# NUC100DN_v1 register map
File version: 1.0
Registers are 32-bit, read-write, reset 0x0 unless marked. A register's access mark holds for its fields unless they carry their own. Offsets are from the block's base; [hi:lo] are bit positions.

## SC0 — SC Register Map
Base 0x40190000
Same registers: SC1 0x40194000, SC2 0x40198000
0x00 SC_RBR ro reset not defined — SC Receiving Buffer Register.
  [7:0] RBR — Receive Buffer Register. By reading this register, the SC will return an 8-bit received data.
0x00 SC_THR wo reset not defined (alternate view of SC_RBR) — SC Transmit Holding Register
  [7:0] THR — Transmit Holding Register. By writing to this register, the SC will send out an 8-bit data. Note: If SC_CTL[SC_CEN] not enabled, this register cannot be programmed.
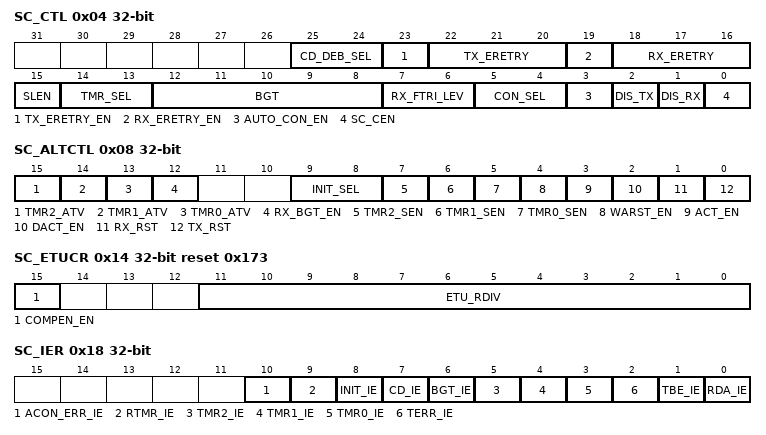
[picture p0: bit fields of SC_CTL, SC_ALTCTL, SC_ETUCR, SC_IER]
0x04 SC_CTL — SC Control Register
  [25:24] CD_DEB_SEL — Card Detect De-bounce Selection. This field indicates the card detect de-bounce selection.
    0=De-bounce sample card insert once per 384 (128 * 3) peripheral clocks and de-bounce sample card removal once per 128 peripheral clocks; 1=De-bounce sample card insert once per 192 (64 * 3) peripheral clocks and de-bounce sample card removal once per 64 peripheral clocks; 2=De-bounce sample card insert once per 96 (32 * 3) peripheral clocks and de-bounce sample card removal once per 32 peripheral clocks; 3=De-bounce sample card insert once per 48 (16 * 3) peripheral clocks and de-bounce sample card removal once per 16 peripheral clocks
  [23] TX_ERETRY_EN — TX Error Retry Enable Bit. This bit enables transmitter retry function when parity error has occurred. Note: Software must fill in TX_ERETRY value before enabling this bit.
    0=TX error retry function Disabled; 1=TX error retry function Enabled
  [22:20] TX_ERETRY — TX Error Retry Count. This field indicates the maximum number of transmitter retries that are allowed when parity error has occurred. Note1: The real retry number is TX_ERETRY + 1, and 8 is the maximum retry number. Note2: This field cannot be changed when TX_ERETRY_EN is enabled. The change flow is to disable TX_ETRTRY_EN first and then fill in a new retry value.
  [19] RX_ERETRY_EN — RX Error Retry Enable Bit. This bit enables receiver retry function when parity error has occurred. Note: Software must fill in RX_ERETRY value before enabling this bit.
    0=RX error retry function Disabled; 1=RX error retry function Enabled
  [18:16] RX_ERETRY — RX Error Retry Count. This field indicates the maximum number of receiver retries that are allowed when parity error has occurred. Note1: The real maximum retry number is RX_ERETRY + 1, so 8 is the maximum retry number. Note2: This field cannot be changed when RX_ERETRY_EN enabled. The change flow is to disable RX_ETRTRY_EN first and then fill new retry value.
  [15] SLEN — Stop Bit Length. This field indicates the length of stop bit. Note: The default stop bit length is 2.
    0=The stop bit length is 2 ETU; 1=The stop bit length is 1 ETU
  [14:13] TMR_SEL — Timer Selection
    0=All internal timer functions Disabled; 1=Internal 24-bit timer Enabled. Software can configure it by setting SC_TMR0 [23:0]. SC_TMR1 and SC_TMR2 will be ignored in this mode; 2=Internal 24-bit timer and 8-bit internal timer Enabled. Software can configure the 24-bit timer by setting SC_TMR0 [23:0] and configure the 8-bit timer by setting SC_TMR1[7:0]. SC_TMR2 will be ignored in this mode; 3=Internal 24-bit timer and two 8-bit timers Enabled. Software can configure them by setting SC_TMR0 [23:0], SC_TMR1 [7:0] and SC_TMR2 [7:0]
  [12:8] BGT — Block Guard Time (BGT). Note: The real block guard time is BGT + 1.
  [7:6] RX_FTRI_LEV — Rx Buffer Trigger Level. When the number of bytes in the receiving buffer equals the RX_FTRI_LEV, the RDA_IF will be set (if IER [RDA_IEN] is enabled, an interrupt will be generated).
    0=INTR_RDA Trigger Level with 1 Byte; 1=INTR_RDA Trigger Level with 2 Bytes; 2=INTR_RDA Trigger Level with 3 Bytes
  [5:4] CON_SEL — Convention Selection. Note: If AUTO_CON_EN enabled, this fields must be ignored.
    0=Direct convention; 3=Inverse convention
  [3] AUTO_CON_EN — Auto Convention Enable Bit
    0=Auto-convention Disabled; 1=Auto-convention Enabled
  [2] DIS_TX — TX Transition Disable Bit
    0=Transceiver Enabled; 1=Transceiver Disabled
  [1] DIS_RX — RX Transition Disable Bit. Note: If AUTO_CON_EN enabled, this fields must be ignored.
    0=Receiver Enabled; 1=Receiver Disabled
  [0] SC_CEN — SC Engine Enable Bit. Setting this bit to "1" will enable SC operation. If this bit is cleared, SC will force all transition to IDLE state.
0x08 SC_ALTCTL — SC Alternate Control State Register
  [15] TMR2_ATV ro — Internal Timer2 Active State (Read Only). This bit indicates the Timer2 counter status
    0=Timer2 is not active; 1=Timer2 is active
  [14] TMR1_ATV ro — Internal Timer1 Active State (Read Only). This bit indicates the Timer1 counter status
    0=Timer1 is not active; 1=Timer1 is active
  [13] TMR0_ATV ro — Internal Timer0 Active State (Read Only). This bit indicates the Timer0 counter status
    0=Timer0 is not active; 1=Timer0 is active
  [12] RX_BGT_EN — Check Receiver Block Guard Time Function Enable
    0=Check receiver block guard time function Disabled; 1=Check receiver block guard time function Enabled
  [9:8] INIT_SEL — Initial Timing Selection. This fields indicates the timing of hardware initial state (activation or warm-reset or deactivation). Unit: SC clock. Activation: refer to Figure 679. Warm-reset: refer to Figure 680. Deactivation: refer to Figure 681.
  [7] TMR2_SEN — Internal Timer2 Start Enable Bit. This bit enables Timer2 to start counting. Software can fill "0" to stop it and set "1" to reload and count. Note3: This field will be cleared when software set SC_ALTCTL[TX_RST] or SC_ALTCTL [RX_RST] to 1. So don't fill this bit, TX_RST, and RX_RST at the same time. Note4: If SC_CTL [SC_CEN] not enabled, this field cannot be programmed.
    0=Stops counting; 1=Starts counting
  [6] TMR1_SEN — Internal Timer1 Start Enable Bit. This bit enables Timer1 to start counting. Software can fill "0" to stop it and set "1" to reload and count. Note3: This field will be cleared when software set SC_ALTCTL[TX_RST] or SC_ALTCTL[RX_RST] to 1, so don't fill this bit, TX_RST, and RX_RST at the same time. Note4: If SC_CTL [SC_CEN] not enabled, this field cannot be programmed.
    0=Stops counting; 1=Starts counting
  [5] TMR0_SEN — Internal Timer0 Start Enable Bit. This bit enables Timer0 to start counting. Software can fill "0" to stop it and set "1" to reload and count. Note3: This field will be cleared when software set SC_ALTCTL[TX_RST] or SC_ALTCTL[RX_RST] to 1. So don't fill this bit, TX_RST and RX_RST at the same time. Note4: If SC_CTL [SC_CEN] not enabled, this field cannot be programmed.
    0=Stops counting; 1=Starts counting
  [4] WARST_EN — Warm Reset Sequence Generator Enable Bit. This bit enables SC controller to initiate the card by warm reset sequence. Note1: When the warm reset sequence completed, this bit will be cleared automatically and the SC_ISR[INIT_IS] will be set to "1". Note2: This field will be cleared when software set SC_ALTCTL[TX_RST] or SC_ALTCTL[RX_RST] to 1. So don't fill this bit, TX_RST, and RX_RST at the same time. Note3: If SC_CTL[SC_CEN] not enabled, this field cannot be programmed.
    0=No effect; 1=Warm reset sequence generator Enabled
  [3] ACT_EN — Activation Sequence Generator Enable Bit. This bit enables SC controller to initiate the card by activation sequence. Note1: When the activation sequence completed, this bit will be cleared automatically and the SC_ISR [INIT_IS] will be set to "1". Note2: This field will be cleared when software set SC_ALTCTL[TX_RST] or SC_ALTCTL[RX_RST] to 1. So don't fill this bit, TX_RST, and RX_RST at the same time. Note3: If SC_CTL[SC_CEN] not enabled, this field cannot be programmed.
    0=No effect; 1=Activation sequence generator Enabled
  [2] DACT_EN — Deactivation Sequence Generator Enable Bit. This bit enables SC controller to initiate the card by deactivation sequence. Note1: When the deactivation sequence completed, this bit will be cleared automatically and the SC_ISR [INIT_IS] will be set to "1". Note2: This field will be cleared when software set SC_ALTCTL[TX_RST] or SC_ALTCTL[RX_RST] to 1. So don't fill this bit, TX_RST, and RX_RST at the same time. Note3: If SC_CTL [SC_CEN] not enabled, this field cannot be programmed.
    0=No effect; 1=Deactivation sequence generator Enabled
  [1] RX_RST — Rx Software Reset. When RX_RST is set, all the bytes in the receiver buffer and Rx internal state machine will be cleared. Note: This bit will be auto cleared and it needs at least 3 SC peripheral clock cycles.
    0=No effect; 1=Reset the Rx internal state machine and pointers
  [0] TX_RST — TX Software Reset. When TX_RST is set, all the bytes in the transmit buffer and TX internal state machine will be cleared. Note: This bit will be auto cleared and it needs at least 3 SC peripheral clock cycles.
    0=No effect; 1=Reset the TX internal state machine and pointers
0x0C SC_EGTR — SC Extend Guard Time Register
  [7:0] EGT — Extended Guard Time. This field indicates the extended guard time value. Note: The counter is ETU based and the real extended guard time is EGT.
0x10 SC_RFTMR — SC Receiver Buffer Time-out Register
  [8:0] RFTM — SC Receiver Buffer Time-out Register (ETU Based). Note1: The counter unit is ETU based and the interval of time-out is RFTM + 0.5. Note2: Filling all "0" to this field indicates to disable this function.
0x14 SC_ETUCR reset 0x173 — SC ETU Control Register
  [15] COMPEN_EN — Compensation Mode Enable Bit. This bit enables clock compensation function. When this bit enabled, hardware will alternate between n-1 clock cycles and n clock cycles, where n is the value to be written into the ETU_RDIV register.
    0=Compensation function Disabled; 1=Compensation function Enabled
  [11:0] ETU_RDIV — ETU Rate Divider. The field indicates the clock rate divider. The real ETU is ETU_RDIV + 1. Note1: Software can configure this field, but this field must be greater than 0x04. Note2: Software can configure this field, but if the error rate is equal to 2%, this field must be greater than 0x040.
0x18 SC_IER — SC Interrupt Enable Register
  [10] ACON_ERR_IE — Auto Convention Error Interrupt Enable Bit. This field is used for auto-convention error interrupt enable.
    0=Auto-convention error interrupt Disabled; 1=Auto-convention error interrupt Enabled
  [9] RTMR_IE — Receiver Buffer Time-out Interrupt Enable Bit. This field is used for receiver buffer time-out interrupt enable.
    0=Receiver buffer time-out interrupt Disabled; 1=Receiver buffer time-out interrupt Enabled
  [8] INIT_IE — Initial End Interrupt Enable Bit. This field is used for activation (SC_ALTCTL [ACT_EN]), deactivation (SC_ALTCTL [DACT_EN]) and warm reset (SC_ALTCTL [WARST_EN]) sequence interrupt enable.
    0=Initial end interrupt Disabled; 1=Initial end interrupt Enabled
  [7] CD_IE — Card Detect Interrupt Enable Bit. This field is used for card detect interrupt enable. The card detect status register is SC_PINCSR[CD_INS_F] and SC_PINCSR[CD_REM_F].
    0=Card detect interrupt Disabled; 1=Card detect interrupt Enabled
  [6] BGT_IE — Block Guard Time Interrupt Enable Bit. This field is used for block guard time interrupt enable.
    0=Block guard time Disabled; 1=Block guard time Enabled
  [5] TMR2_IE — Timer2 Interrupt Enable Bit. This field is used for TMR2 interrupt enable.
    0=Timer2 interrupt Disabled; 1=Timer2 interrupt Enabled
  [4] TMR1_IE — Timer1 Interrupt Enable Bit. This field is used for TMR1 interrupt enable.
    0=Timer1 interrupt Disabled; 1=Timer1 interrupt Enabled
  [3] TMR0_IE — Timer0 Interrupt Enable Bit. This field is used for TMR0 interrupt enable.
    0=Timer0 interrupt Disabled; 1=Timer0 interrupt Enabled
  [2] TERR_IE — Transfer Error Interrupt Enable Bit. This field is used for transfer error interrupt enable. The transfer error states is at SC_TRSR register which includes receiver break error (RX_EBR_F), frame error (RX_EFR_F), parity error (RX_EPA_F), receiver buffer overflow error (RX_OVER_F), transmit buffer overflow error (TX_OVER_F), receiver retry over limit error (RX_OVER_REERR) and transmitter retry over limit error (TX_OVER_REERR).
    0=Transfer error interrupt Disabled; 1=Transfer error interrupt Enabled
  [1] TBE_IE — Transmit Buffer Empty Interrupt Enable Bit. This field is used for transmit buffer empty interrupt enable.
    0=Transmit buffer empty interrupt Disabled; 1=Transmit buffer empty interrupt Enabled
  [0] RDA_IE — Receive Data Reach Interrupt Enable Bit. This field is used for received data reaching trigger level (SC_CTL [RX_FTRI_LEV]) interrupt enable.
    0=Receive data reach trigger level interrupt Disabled; 1=Receive data reach trigger level interrupt Enabled
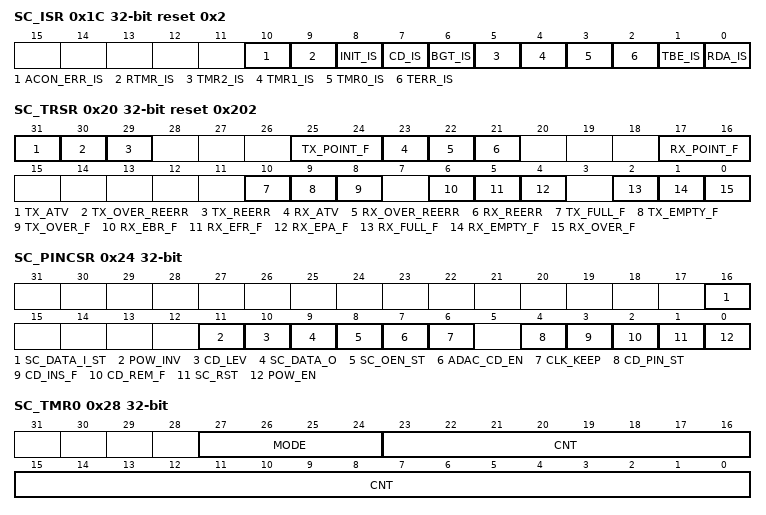
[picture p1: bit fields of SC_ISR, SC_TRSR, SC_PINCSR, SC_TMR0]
0x1C SC_ISR reset 0x2 — SC Interrupt Status Register
  [10] ACON_ERR_IS ro — Auto Convention Error Interrupt Status Flag (Read Only). This field indicates auto convention sequence error. If the received TS at ATR state is not 0x3B or 0x3F, this bit will be set. Note: This bit is read only, but can be cleared by writing "1" to it.
  [9] RTMR_IS ro — Receiver Buffer Time-out Interrupt Status Flag (Read Only). This field is used for receiver buffer time-out interrupt status flag. Note: This field is the status flag of receiver buffer time-out state. If software wants to clear this bit, software must read the receiver buffer remaining data by reading SC_RBR register,
  [8] INIT_IS ro — Initial End Interrupt Status Flag (Read Only). This field is used for activation (SC_ALTCTL [ACT_EN]), deactivation (SC_ALTCTL [DACT_EN]) and warm reset (SC_ALTCTL [WARST_EN]) sequence interrupt status flag. Note: This bit is read only, but it can be cleared by writing "1" to it.
  [7] CD_IS ro — Card Detect Interrupt Status Flag (Read Only). Note: If software wants to clear this field, software must clear SC_PINCSR [CD_INS_F] and SC_PINCSR [CD_REM_F].
  [6] BGT_IS ro — Block Guard Time Interrupt Status Flag (Read Only). This field is used for block guard time interrupt status flag. Note1: This bit is valid when SC_ALTCTL[RX_BGT_EN] is enabled. Note2: This bit is read only, but it can be cleared by writing "1" to it.
  [5] TMR2_IS ro — Timer2 Interrupt Status Flag (Read Only). This field is used for TMR2 interrupt status flag. Note: This bit is read only, but it can be cleared by writing "1" to it.
  [4] TMR1_IS ro — Timer1 Interrupt Status Flag (Read Only). This field is used for TMR1 interrupt status flag. Note: This bit is read only, but it can be cleared by writing "1" to it.
  [3] TMR0_IS ro — Timer0 Interrupt Status Flag (Read Only). This field is used for TMR0 interrupt status flag. Note: This bit is read only, but it can be cleared by writing "1" to it.
  [2] TERR_IS ro — Transfer Error Interrupt Status Flag (Read Only). This field is used for transfer error interrupt status flag. The transfer error status is at the SC_TRSR register which includes receiver break error (RX_EBR_F), frame error (RX_EFR_F), parity error (RX_EPA_F) and receiver buffer overflow error (RX_OVER_F), transmit buffer overflow error (TX_OVER_F), receiver retry over limit error (RX_OVER_REERR) and transmitter retry over limit error (TX_OVER_REERR). Note: This field is the status flag of SC_TRSR[RX_EBR_F], SC_TRSR[RX_EFR_F], SC_TRSR[RX_EPA_F], SC_TRSR[RX_OVER_F], SC_TRSR[TX_OVER_F], SC_TRSR[RX_OVER_REERR] or SC_TRSR[TX_OVER_REERR]. So if software wants to clear this bit, software must write "1" to each field.
  [1] TBE_IS ro — Transmit Buffer Empty Interrupt Status Flag (Read Only). This field is used for transmit buffer empty interrupt status flag. Note: This field is the status flag of transmit buffer empty state. If software wants to clear this bit, software must write data to SC_THR register and then this bit will be cleared automatically.
  [0] RDA_IS ro — Receive Data Reach Interrupt Status Flag (Read Only). This field is used for received data reaching trigger level (SC_CTL[RX_FTRI_LEV]) interrupt status flag. Note: This field is the status flag of received data reaching SC_CTL [RX_FTRI_LEV]. If software reads data from SC_RBR and receiver pointer is less than SC_CTL [RX_FTRI_LEV], this bit will be cleared automatically.
0x20 SC_TRSR reset 0x202 — SC Transfer Status Register
  [31] TX_ATV ro — Transmit in Active Status Flag (Read Only). This bit is set by hardware when TX transfer is in active and the STOP bit of the last byte has not been transmitted. This bit is cleared automatically when TX transfer is finished or the last byte transmission has completed.
  [30] TX_OVER_REERR ro — Transmitter over Retry Error (Read Only). This bit is set by hardware when transmitter re-transmits over retry number limitation. Note: This bit is read only, but it can be cleared by writing "1" to it.
  [29] TX_REERR ro — Transmitter Retry Error (Read Only). This bit is set by hardware when transmitter re-transmits. Note1: This bit is read only, but it can be cleared by writing "1" to it. Note2: This bit is a flag and cannot generate any interrupt to CPU.
  [25:24] TX_POINT_F ro — Transmit Buffer Pointer Status Flag (Read Only). This field indicates the TX buffer pointer status flag. When CPU writes data into SC_THR, TX_POINT_F increases one. When one byte of TX Buffer is transferred to transmitter shift register, TX_POINT_F decreases one.
  [23] RX_ATV ro — Receiver in Active Status Flag (Read Only). This bit is set by hardware when RX transfer is in active. This bit is cleared automatically when RX transfer is finished.
  [22] RX_OVER_REERR ro — Receiver over Retry Error (Read Only). This bit is set by hardware when RX transfer error retry over retry number limit. Note1: This bit is read only, but it can be cleared by writing "1" to it. Note2: If CPU enables receiver retries function by setting SC_CTL [RX_ERETRY_EN] register, the RX_EPA_F flag will be ignored (hardware will not set RX_EPA_F).
  [21] RX_REERR ro — Receiver Retry Error (Read Only). This bit is set by hardware when RX has any error and retries transfer. Note1: This bit is read only, but it can be cleared by writing "1" to it. Note2 This bit is a flag and cannot generate any interrupt to CPU. Note3: If CPU enables receiver retry function by setting SC_CTL [RX_ERETRY_EN] register, the RX_EPA_F flag will be ignored (hardware will not set RX_EPA_F).
  [17:16] RX_POINT_F ro — Receiver Buffer Pointer Status Flag (Read Only). This field indicates the RX buffer pointer status flag. When SC receives one byte from external device, RX_POINT_F increases one. When one byte of RX buffer is read by CPU, RX_POINT_F decreases one.
  [10] TX_FULL_F ro — Transmit Buffer Full Status Flag (Read Only). This bit indicates TX buffer full or not. This bit is set when TX pointer is equal to 4, otherwise is cleared by hardware.
  [9] TX_EMPTY_F ro — Transmit Buffer Empty Status Flag (Read Only). This bit indicates TX buffer empty or not. When the last byte of TX buffer has been transferred to Transmitter Shift Register, hardware sets this bit high. It will be cleared when writing data into SC_THR (TX buffer not empty).
  [8] TX_OVER_F ro — TX Overflow Error Interrupt Status Flag (Read Only). If TX buffer is full, an additional write to SC_THR will cause this bit be set to "1" by hardware. Note: This bit is read only, but it can be cleared by writing "1" to it.
  [6] RX_EBR_F ro — Receiver Break Error Status Flag (Read Only). This bit is set to "1" whenever the received data input (RX) held in the "spacing state" (logic "0") is longer than a full word transmission time (that is, the total time of "start bit" + data bits + parity + stop bits). . Note1: This bit is read only, but it can be cleared by writing "1" to it. Note2: If CPU sets receiver retries function by setting SC_CTL[RX_ERETRY_EN] register, hardware will not set this flag.
  [5] RX_EFR_F ro — Receiver Frame Error Status Flag (Read Only). This bit is set to "1" whenever the received character does not have a valid "STOP bit" (that is, the STOP bit following the last data bit or parity bit is detected as logic 0). Note1: This bit is read only, but can be cleared by writing "1" to it. Note2: If CPU sets receiver retries function by setting SC_CTL[RX_ERETRY_EN] register, hardware will not set this flag.
  [4] RX_EPA_F ro — Receiver Parity Error Status Flag (Read Only). This bit is set to "1" whenever the received character does not have a valid "parity bit". Note1: This bit is read only, but it can be cleared by writing "1" to it. Note2: If CPU sets receiver retries function by setting SC_CTL[RX_ERETRY_EN] register, hardware will not set this flag.
  [2] RX_FULL_F ro — Receiver Buffer Full Status Flag (Read Only). This bit indicates RX buffer full or not. This bit is set when RX pointer is equal to 4, otherwise it is cleared by hardware.
  [1] RX_EMPTY_F ro — Receiver Buffer Empty Status Flag(Read Only). This bit indicates RX buffer empty or not. When the last byte of RX buffer has been read by CPU, hardware set this bit to "1". It will be cleared by hardware when SC receives any new data.
  [0] RX_OVER_F ro — RX Overflow Error Status Flag (Read Only). This bit is set when RX buffer overflow. If the number of received bytes is greater than Rx Buffer size (4 bytes), this bit will be set. Note: This bit is read only, but it can be cleared by writing "1" to it.
0x24 SC_PINCSR (reset mask 0xFFF0FF0F) — SC Pin Control State Register
  [16] SC_DATA_I_ST ro — SC Data Pin Status (Read Only). This bit is the pin status of SC_DATA
    0=The SC_DATA pin is low; 1=The SC_DATA pin is high
  [11] POW_INV — SC_PWR Pin Inverse. This bit is used for inverse the SC_PWR pin. There are four kinds of combination for SC_PWR pin setting by POW_INV(SC_PINCSR[11]) and POW_EN(SC_PINCSR[0]). POW_INV(SC_PINCSR[11]) is bit 1 and POW_EN(SC_PINCSR[0]) is bit 0 for SC_PWR Pin as high or low voltage selection. Note: Software must select POW_INV before Smart Card engine is enabled.
  [10] CD_LEV — Card Detect Level. Note: Software must select card detect level before Smart Card engine is enabled
    0=When hardware detects the card detect pin from high to low, it indicates a card is detected; 1=When hardware detects the card detect pin from low to high, it indicates a card is detected
  [9] SC_DATA_O — SC Data Output Pin. This bit is the pin status of SC_DATA but user can drive SC_DATA pin to high or low by setting this bit. Write this field to drive SC_DATA pin. Note: When SC is at activation, warm reset or deactivation mode, this bit will be changed automatically. So don't fill this field when SC is in these modes.
    0=Drive SC_DATA pin to low. SC_DATA pin status is low; 1=Drive SC_DATA pin to high. SC_DATA pin status is high
  [8] SC_OEN_ST ro — SC Data Output Enable Pin Status (Read Only). This bit is the output enable status of the SC_DATA pin
    0=The SC_DATA pin state is output; 1=The SC_DATA pin state is not output
  [7] ADAC_CD_EN — Auto Deactivation When Card Removal. Note: When the card is removed, hardware will stop any process and then do deactivation sequence (if this bit be setting). If this process completes. Hardware will generate an initial end interrupt to CPU.
    0=Auto deactivation Disabled when hardware detected the card removal; 1=Auto deactivation Enabled when hardware detected the card removal
  [6] CLK_KEEP — SC Clock Enable Bit. Note: When operating at activation, warm reset or deactivation mode, this bit will be changed automatically. So don't fill this field when operating in these modes.
    0=SC clock generation Disabled; 1=SC clock always keeps free running
  [4] CD_PIN_ST ro — Card Detect Status of SC_CD Pin Status (Read Only). This bit is the pin status flag of SC_CD
    0=The SC_CD pin state at low; 1=The SC_CD pin state at high
  [3] CD_INS_F ro — Card Detect Insert Status of SC_CD Pin (Read Only). This bit is set whenever card has been inserted. Note1: This bit is read only, but it can be cleared by writing "1" to it. Note2: The card detect engine will start after SC_CTL[SC_CEN] set.
    0=No effect; 1=Card insert
  [2] CD_REM_F ro — Card Detect Removal Status of SC_CD Pin (Read Only). This bit is set whenever a card has been removed. Note1: This bit is read only, but it can be cleared by writing "1" to it. Note2: Card detect engine will start after SC_CTL[SC_CEN] set.
    0=No effect; 1=Card removed
  [1] SC_RST — SC_RST Pin Signal. This bit is the pin status of SC_RST but user can drive SC_RST pin to high or low by setting this bit. Write this field to drive SC_RST pin. Note: When operating at activation, warm reset or deactivation mode, this bit will be changed automatically. So don't fill this field when operating in these modes.
    0=Drive SC_RST pin to low. SC_RST pin status is low; 1=Drive SC_RST pin to high. SC_RST pin status is high
  [0] POW_EN — SC_POW_EN Pin Signal. Software can set POW_EN and POW_INV to decide SC_PWR pin is in high or low level. Write this field to drive SC_PWR pin. Refer POW_INV(SC_PINCSR[11]) description for programming SC_PWR pin voltage level. Read this field to get SC_PWR pin status. Note: When operating at activation, warm reset or deactivation mode, this bit will be changed automatically. So don't fill this field when operating in these modes.
    0=SC_PWR pin status is low; 1=SC_PWR pin status is high
0x28 SC_TMR0 — SC Internal Timer Control Register 0
  [27:24] MODE — Timer 0 Operation Mode Selection. This field indicates the internal 24-bit timer operation selection. Refer to Table 622 for programming Timer0
  [23:0] CNT — Timer 0 Counter Value Register (ETU Based). This field indicates the internal timer operation values.
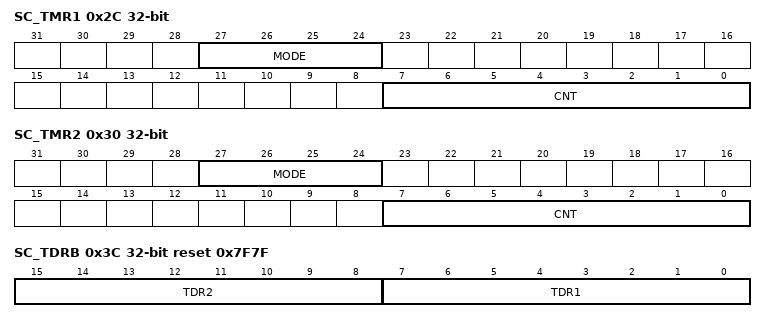
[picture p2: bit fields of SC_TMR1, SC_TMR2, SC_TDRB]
0x2C SC_TMR1 — SC Internal Timer Control Register 1
  [27:24] MODE — Timer 1 Operation Mode Selection. This field indicates the internal 8-bit timer operation selection. Refer to Table 622 for programming Timer1
  [7:0] CNT — Timer 1 Counter Value Register (ETU Based). This field indicates the internal timer operation values.
0x30 SC_TMR2 — SC Internal Timer Control Register 2
  [27:24] MODE — Timer 2 Operation Mode Selection. This field indicates the internal 8-bit timer operation selection. Refer to Table 622 for programming Timer2
  [7:0] CNT — Timer 2 Counter Value Register (ETU Based). This field indicates the internal timer operation values.
0x38 SC_TDRA ro reset 0x7FF — SC Timer Current Data Register A
  [23:0] TDR0 — Timer0 Current Data Register (Read Only). This field indicates the current count values of timer0.
0x3C SC_TDRB ro reset 0x7F7F — SC Timer Current Data Register B
  [15:8] TDR2 — Timer2 Current Data Register (Read Only). This field indicates the current count values of timer2.
  [7:0] TDR1 — Timer1 Current Data Register (Read Only). This field indicates the current count values of timer1.
